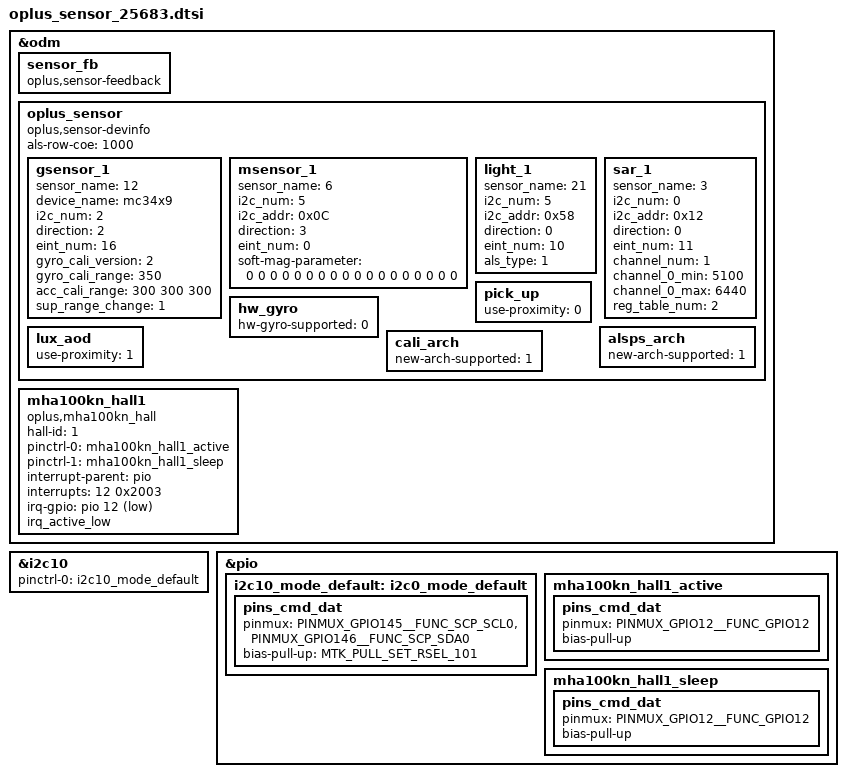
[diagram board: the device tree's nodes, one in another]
&odm {
	sensor_fb: sensor_fb {
		compatible = "oplus,sensor-feedback";
	};
	oplus_sensor:oplus_sensor {
		compatible = "oplus,sensor-devinfo";
		als-row-coe = <1000>;
		/* sensor start */
		/*
		enum {
			LIS3DH,
			LSM6DS3,
			BMI160,
			LIS2HH12,
			LSM6DSM,
			BMI2XY,
			LSM6DSO,
			ICM4X6XX,
			ICM4263X,
			ICM4N607,
			BMI22X,
			SC7A20,
			MC34X9,
			BMA4XY,
			STK8329,
			BMI3XY,
			ICM456XY,
		};
		*/
		gsensor_1: gsensor_1 {
			status = "okay";
			sensor_name = <12>; // ICM456XY
			device_name = "mc34x9";
			i2c_num = <2>;
			direction = <2>;
			eint_num = <16>;
			gyro_cali_version= <2>;
			gyro_cali_range =<350>;
			acc_cali_range= <300 300 300>;
			sup_range_change = <1>;
		};

		/*
		enum {
			AKM09911,
			MMC3530,
			MMC5603,
			MXG4300,
			AKM09918,
			AKM09919,
			AF6133E,
		};
		*/
		msensor_1: msensor_1 {
			status = "okay";
			sensor_name = <6>; // AF6133E
			i2c_num = <5>;
			i2c_addr = <0x0C>;
			direction = <3>;
			eint_num = <0>;
			soft-mag-parameter = <0 0 0 0 0 0 0 0 0 0 0 0 0 0 0 0 0 0>;
		};
		/*
		enum {
			TMD2725,
			APSD9922,
			STK3335,
			STK3331,
			STK2232,
			TCS3701,
			STK32600,
			STK33502,
			MN78911,
			TCS3720,
			SIP3515,
			STK3329,
			LTR569,
			SIP3510,
			SIP3625,
			STK33C01,
			SIP3535,
			STK63701,
			TMD2765,
			TCS3743,
			SIP3511,
			SIP1221LR1S,
		};
		*/
		light_1: light_1 {
			status = "okay";
			sensor_name = <21>; // SIP1221LR1S
			i2c_num = <5>;
			i2c_addr = <0x58>;
			direction = <0>;
			eint_num = <10>;
			als_type = <1>;
		};
		/*
		enum {
			SX933x,
			SX937x,
			AW9610X,
			AW963XX,
		};
		*/
		sar_1: sar_1 {
			status = "okay";
			sensor_name = <3>; // AW963XX
			i2c_num = <0>;
			i2c_addr = <0x12>;
			direction = <0>;
			eint_num = <11>;
			channel_num = <1>;
			channel_0_min = <5100>;
			channel_0_max = <6440>;
			reg_table_num = <2>;
		};
		hw_gyro: hw_gyro {
			status = "okay";
			hw-gyro-supported = <0>;
		};
		pick_up: pick_up {
			status = "okay";
			use-proximity = <0>;
		};
		lux_aod: lux_aod {
			status = "okay";
			use-proximity = <1>;
		};
		alsps_arch: alsps_arch {
			status = "okay";
			new-arch-supported = <1>;
		};
		cali_arch: cali_arch {
			status = "okay";
			new-arch-supported = <1>;
		};
	};
/* sensor end */
};

/* sar start */
&i2c10 {
	pinctrl-names = "default";
	pinctrl-0 = <&i2c10_mode_default>;
};

&pio {
	i2c10_mode_default: i2c0_mode_default {
		pins_cmd_dat {
			pinmux = <PINMUX_GPIO145__FUNC_SCP_SCL0>,
					<PINMUX_GPIO146__FUNC_SCP_SDA0>;
			/* 0x0:75k 0x1:3k 0x2:5k 0x3:1.5k */
			/* 0x4:10k 0x5:2k 0x6:4k 0x7:1k */
			bias-pull-up = <MTK_PULL_SET_RSEL_101>;
		};
	};
};
/* sar end */

/* hall */
&odm {
	mha100kn_hall1: mha100kn_hall1 {
		compatible = "oplus,mha100kn_hall";
		hall-id = <1>;
		pinctrl-names = "mha100kn_hall1_active" , "mha100kn_hall1_sleep";

		pinctrl-0 = <&mha100kn_hall1_active>;
		pinctrl-1 = <&mha100kn_hall1_sleep>;

		interrupt-parent = <&pio>;
		interrupts = <12 0x2003>;      //both rising and falling edge
		irq-gpio = <&pio 12 0x2003>;
		irq_active_low;
	};
};
&pio {
	mha100kn_hall1_active: mha100kn_hall1_active {
		pins_cmd_dat {
			pinmux = <PINMUX_GPIO12__FUNC_GPIO12>;
			bias-pull-up;
		};
	};
	mha100kn_hall1_sleep: mha100kn_hall1_sleep {
		pins_cmd_dat {
			pinmux = <PINMUX_GPIO12__FUNC_GPIO12>;
			bias-pull-up;
		};
	};
};
/* hall */
